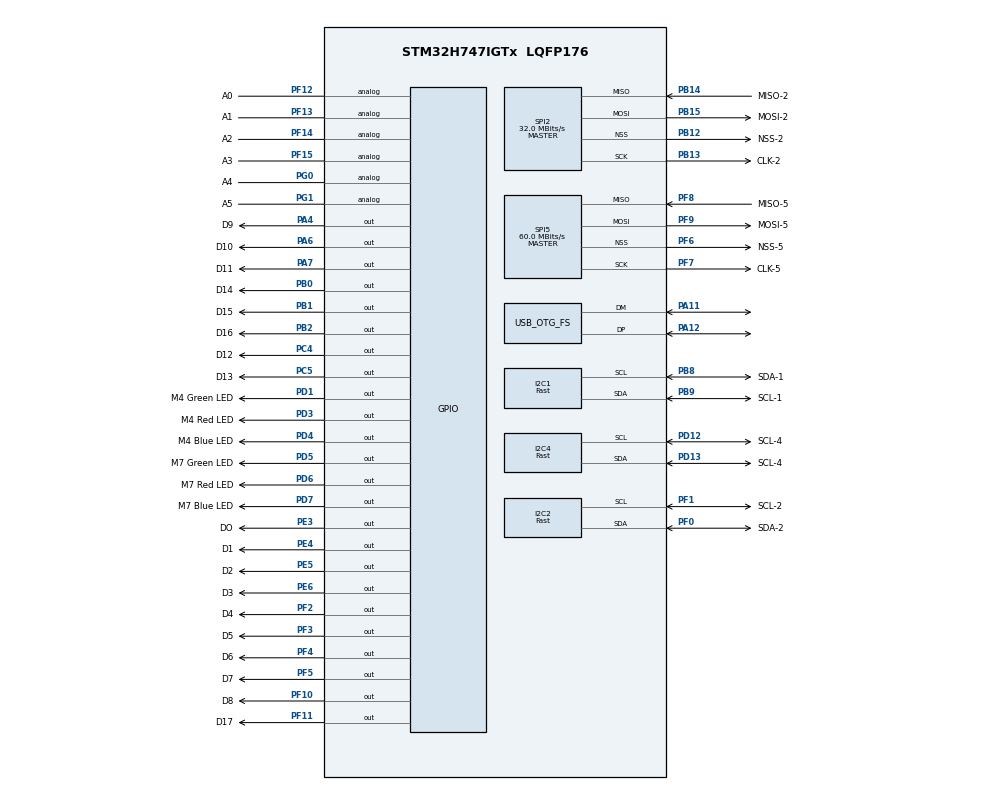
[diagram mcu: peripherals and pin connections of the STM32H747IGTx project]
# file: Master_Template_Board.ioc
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CORTEX_M7.CPU_DCache=Enabled
CORTEX_M7.CPU_ICache=Enabled
CORTEX_M7.default_mode_Activation=1
CortexM4.IPs=CORTEX_M4\:I,FATFS_M4\:I,FREERTOS_M4\:I,IWDG2\:I,OPENAMP_M4\:I,PDM2PCM_M4\:I,PWR,RCC,RESMGR_UTILITY,SYS_M4\:I,USB_DEVICE_M4\:I,USB_HOST_M4\:I,VREFBUF,WWDG2\:I,GPIO,DMA,BDMA,MDMA,NVIC2\:I,I2C1,I2C2,I2C4,SPI2,SPI5,DEBUG
CortexM4.Pins=PE3,PE4,PE5,PE6,PF2,PF3,PF4,PF5,PF10,PA4,PA6,PA7,PC4,PC5,PB0,PB1,PB2,PF11,PF12,PF13,PF14,PF15,PG0,PG1,PD1,PD3,PD4
CortexM7.IPs=CORTEX_M7\:I,FATFS_M7\:I,FREERTOS_M7\:I,IWDG1\:I,OPENAMP_M7\:I,PDM2PCM_M7\:I,PWR\:I,RCC\:I,RESMGR_UTILITY\:I,SYS\:I,USB_DEVICE_M7\:I,USB_HOST_M7\:I,VREFBUF\:I,WWDG1\:I,GPIO\:I,DMA\:I,BDMA\:I,MDMA\:I,NVIC1\:I,I2C1\:I,I2C2\:I,I2C4\:I,SPI2\:I,SPI5\:I,USB_OTG_FS\:I,DEBUG\:I,MEMORYMAP\:I
CortexM7.Pins=PD5,PD6,PD7
I2C1.I2C_Speed_Mode=I2C_Fast
I2C1.Timing=0x00B03FDB
I2C2.I2C_Speed_Mode=I2C_Fast
I2C2.Timing=0x00B03FDB
I2C4.I2C_Speed_Mode=I2C_Fast
I2C4.Timing=0x00B03FDB
Mcu.Family=STM32H7
Mcu.Name=STM32H747IGTx
Mcu.Package=LQFP176
NVIC1.OTG_FS_IRQn=true\:0\:0\:false\:false\:true\:false\:true\:true
NVIC1.PriorityGroup=NVIC_PRIORITYGROUP_4
NVIC2.PriorityGroup=NVIC_PRIORITYGROUP_4
PA11.GPIO_Speed=GPIO_SPEED_FREQ_VERY_HIGH
PA11.Mode=Device_Only
PA11.PinAttribute=CortexM7
PA11.Signal=USB_OTG_FS_DM
PA12.GPIO_Speed=GPIO_SPEED_FREQ_VERY_HIGH
PA12.Mode=Device_Only
PA12.PinAttribute=CortexM7
PA12.Signal=USB_OTG_FS_DP
PA4.GPIO_Label=D9
PA4.GPIO_Speed=GPIO_SPEED_FREQ_VERY_HIGH
PA4.PinAttribute=CortexM4
PA4.Signal=GPIO_Output
PA6.GPIO_Label=D10
PA6.GPIO_Speed=GPIO_SPEED_FREQ_VERY_HIGH
PA6.PinAttribute=CortexM4
PA6.Signal=GPIO_Output
PA7.GPIO_Label=D11
PA7.GPIO_Speed=GPIO_SPEED_FREQ_VERY_HIGH
PA7.PinAttribute=CortexM4
PA7.Signal=GPIO_Output
PB0.GPIO_Label=D14
PB0.GPIO_Speed=GPIO_SPEED_FREQ_VERY_HIGH
PB0.PinAttribute=CortexM4
PB0.Signal=GPIO_Output
PB1.GPIO_Label=D15
PB1.GPIO_Speed=GPIO_SPEED_FREQ_VERY_HIGH
PB1.PinAttribute=CortexM4
PB1.Signal=GPIO_Output
PB12.GPIO_Label=NSS-2
PB12.GPIO_Speed=GPIO_SPEED_FREQ_VERY_HIGH
PB12.Mode=NSS_Signal_Hard_Output
PB12.PinAttribute=CortexM7
PB12.Signal=SPI2_NSS
PB13.GPIO_Label=CLK-2
PB13.Mode=Full_Duplex_Master
PB13.PinAttribute=CortexM7
PB13.Signal=SPI2_SCK
PB14.GPIO_Label=MISO-2
PB14.GPIO_Speed=GPIO_SPEED_FREQ_VERY_HIGH
PB14.Mode=Full_Duplex_Master
PB14.PinAttribute=CortexM7
PB14.Signal=SPI2_MISO
PB15.GPIO_Label=MOSI-2
PB15.GPIO_Speed=GPIO_SPEED_FREQ_VERY_HIGH
PB15.Mode=Full_Duplex_Master
PB15.PinAttribute=CortexM7
PB15.Signal=SPI2_MOSI
PB2.GPIO_Label=D16
PB2.GPIO_Speed=GPIO_SPEED_FREQ_VERY_HIGH
PB2.PinAttribute=CortexM4
PB2.Signal=GPIO_Output
PB8.GPIO_Label=SDA-1
PB8.GPIO_Speed=GPIO_SPEED_FREQ_VERY_HIGH
PB8.Mode=I2C
PB8.PinAttribute=CortexM7
PB8.Signal=I2C1_SCL
PB9.GPIO_Label=SCL-1
PB9.GPIO_Speed=GPIO_SPEED_FREQ_VERY_HIGH
PB9.Mode=I2C
PB9.PinAttribute=CortexM7
PB9.Signal=I2C1_SDA
PC14-OSC32_IN\ (OSC32_IN).Mode=LSE-External-Oscillator
PC14-OSC32_IN\ (OSC32_IN).PinAttribute=Free
PC14-OSC32_IN\ (OSC32_IN).Signal=RCC_OSC32_IN
PC15-OSC32_OUT\ (OSC32_OUT).Mode=LSE-External-Oscillator
PC15-OSC32_OUT\ (OSC32_OUT).PinAttribute=Free
PC15-OSC32_OUT\ (OSC32_OUT).Signal=RCC_OSC32_OUT
PC4.GPIO_Label=D12
PC4.GPIO_Speed=GPIO_SPEED_FREQ_VERY_HIGH
PC4.PinAttribute=CortexM4
PC4.Signal=GPIO_Output
PC5.GPIO_Label=D13
PC5.GPIO_Speed=GPIO_SPEED_FREQ_VERY_HIGH
PC5.PinAttribute=CortexM4
PC5.Signal=GPIO_Output
PD1.GPIO_Label=M4 Green LED
PD1.GPIO_Speed=GPIO_SPEED_FREQ_VERY_HIGH
PD1.PinAttribute=CortexM4
PD1.PinState=GPIO_PIN_SET
PD1.Signal=GPIO_Output
PD12.GPIO_Label=SCL-4
PD12.GPIO_Speed=GPIO_SPEED_FREQ_VERY_HIGH
PD12.Mode=I2C
PD12.PinAttribute=CortexM7
PD12.Signal=I2C4_SCL
PD13.GPIO_Label=SCL-4
PD13.GPIO_Speed=GPIO_SPEED_FREQ_VERY_HIGH
PD13.Mode=I2C
PD13.PinAttribute=CortexM7
PD13.Signal=I2C4_SDA
PD3.GPIO_Label=M4 Red LED
PD3.GPIO_Speed=GPIO_SPEED_FREQ_VERY_HIGH
PD3.PinAttribute=CortexM4
PD3.PinState=GPIO_PIN_SET
PD3.Signal=GPIO_Output
PD4.GPIO_Label=M4 Blue LED
PD4.GPIO_Speed=GPIO_SPEED_FREQ_VERY_HIGH
PD4.PinAttribute=CortexM4
PD4.PinState=GPIO_PIN_SET
PD4.Signal=GPIO_Output
PD5.GPIO_Label=M7 Green LED
PD5.GPIO_Speed=GPIO_SPEED_FREQ_VERY_HIGH
PD5.PinAttribute=CortexM7
PD5.PinState=GPIO_PIN_SET
PD5.Signal=GPIO_Output
PD6.GPIO_Label=M7 Red LED
PD6.GPIO_Speed=GPIO_SPEED_FREQ_VERY_HIGH
PD6.PinAttribute=CortexM7
PD6.PinState=GPIO_PIN_SET
PD6.Signal=GPIO_Output
PD7.GPIO_Label=M7 Blue LED
PD7.GPIO_Speed=GPIO_SPEED_FREQ_VERY_HIGH
PD7.PinAttribute=CortexM7
PD7.PinState=GPIO_PIN_SET
PD7.Signal=GPIO_Output
PE3.GPIO_Label=DO
PE3.GPIO_Speed=GPIO_SPEED_FREQ_VERY_HIGH
PE3.PinAttribute=CortexM4
PE3.Signal=GPIO_Output
PE4.GPIO_Label=D1
PE4.GPIO_Speed=GPIO_SPEED_FREQ_VERY_HIGH
PE4.PinAttribute=CortexM4
PE4.PinState=GPIO_PIN_RESET
PE4.Signal=GPIO_Output
PE5.GPIO_Label=D2
PE5.GPIO_Speed=GPIO_SPEED_FREQ_VERY_HIGH
PE5.PinAttribute=CortexM4
PE5.Signal=GPIO_Output
PE6.GPIO_Label=D3
PE6.GPIO_Speed=GPIO_SPEED_FREQ_VERY_HIGH
PE6.PinAttribute=CortexM4
PE6.Signal=GPIO_Output
PF0.GPIO_Label=SDA-2
PF0.GPIO_Speed=GPIO_SPEED_FREQ_VERY_HIGH
PF0.Mode=I2C
PF0.PinAttribute=CortexM7
PF0.Signal=I2C2_SDA
PF1.GPIO_Label=SCL-2
PF1.GPIO_Speed=GPIO_SPEED_FREQ_VERY_HIGH
PF1.Mode=I2C
PF1.PinAttribute=CortexM7
PF1.Signal=I2C2_SCL
PF10.GPIO_Label=D8
PF10.GPIO_Speed=GPIO_SPEED_FREQ_VERY_HIGH
PF10.PinAttribute=CortexM4
PF10.Signal=GPIO_Output
PF11.GPIO_Label=D17
PF11.GPIO_Speed=GPIO_SPEED_FREQ_VERY_HIGH
PF11.PinAttribute=CortexM4
PF11.Signal=GPIO_Output
PF12.GPIO_Label=A0
PF12.PinAttribute=CortexM4
PF12.Signal=GPIO_Analog
PF13.GPIO_Label=A1
PF13.PinAttribute=CortexM4
PF13.Signal=GPIO_Analog
PF14.GPIO_Label=A2
PF14.PinAttribute=CortexM4
PF14.Signal=GPIO_Analog
PF15.GPIO_Label=A3
PF15.PinAttribute=CortexM4
PF15.Signal=GPIO_Analog
PF2.GPIO_Label=D4
PF2.GPIO_Speed=GPIO_SPEED_FREQ_VERY_HIGH
PF2.PinAttribute=CortexM4
PF2.Signal=GPIO_Output
PF3.GPIO_Label=D5
PF3.GPIO_Speed=GPIO_SPEED_FREQ_VERY_HIGH
PF3.PinAttribute=CortexM4
PF3.Signal=GPIO_Output
PF4.GPIO_Label=D6
PF4.GPIO_Speed=GPIO_SPEED_FREQ_VERY_HIGH
PF4.PinAttribute=CortexM4
PF4.Signal=GPIO_Output
PF5.GPIO_Label=D7
PF5.GPIO_Speed=GPIO_SPEED_FREQ_VERY_HIGH
PF5.PinAttribute=CortexM4
PF5.Signal=GPIO_Output
PF6.GPIO_Label=NSS-5
PF6.GPIO_Speed=GPIO_SPEED_FREQ_VERY_HIGH
PF6.Mode=NSS_Signal_Hard_Output
PF6.PinAttribute=CortexM7
PF6.Signal=SPI5_NSS
PF7.GPIO_Label=CLK-5
PF7.GPIO_Speed=GPIO_SPEED_FREQ_VERY_HIGH
PF7.Mode=Full_Duplex_Master
PF7.PinAttribute=CortexM7
PF7.Signal=SPI5_SCK
PF8.GPIO_Label=MISO-5
PF8.GPIO_Speed=GPIO_SPEED_FREQ_VERY_HIGH
PF8.Mode=Full_Duplex_Master
PF8.PinAttribute=CortexM7
PF8.Signal=SPI5_MISO
PF9.GPIO_Label=MOSI-5
PF9.GPIO_Speed=GPIO_SPEED_FREQ_VERY_HIGH
PF9.Mode=Full_Duplex_Master
PF9.PinAttribute=CortexM7
PF9.Signal=SPI5_MOSI
PG0.GPIO_Label=A4
PG0.PinAttribute=CortexM4
PG0.Signal=GPIO_Analog
PG1.GPIO_Label=A5
PG1.PinAttribute=CortexM4
PG1.Signal=GPIO_Analog
PH0-OSC_IN\ (PH0).Mode=HSE-External-Oscillator
PH0-OSC_IN\ (PH0).PinAttribute=Free
PH0-OSC_IN\ (PH0).Signal=RCC_OSC_IN
PH1-OSC_OUT\ (PH1).Mode=HSE-External-Oscillator
PH1-OSC_OUT\ (PH1).PinAttribute=Free
PH1-OSC_OUT\ (PH1).Signal=RCC_OSC_OUT
ProjectManager.HeapSize=M4-0x200,M7-0x200
ProjectManager.StackSize=M4-0x400,M7-0x400
ProjectManager.TargetToolchain=STM32CubeIDE
RCC.ADCFreq_Value=80000000
RCC.APB1Freq_Value=120000000
RCC.APB2Freq_Value=120000000
RCC.APB3Freq_Value=120000000
RCC.APB4Freq_Value=120000000
RCC.CortexFreq_Value=480000000
RCC.D1PPRE=RCC_APB3_DIV2
RCC.D2PPRE1=RCC_APB1_DIV2
RCC.D2PPRE2=RCC_APB2_DIV2
RCC.D3PPRE=RCC_APB4_DIV2
RCC.DIVM1=2
RCC.DIVM2=1
RCC.DIVN1=120
RCC.DIVN2=10
RCC.HCLKFreq_Value=240000000
RCC.HPRE=RCC_HCLK_DIV2
RCC.HSE_VALUE=16000000
RCC.PLLSourceVirtual=RCC_PLLSOURCE_HSE
RCC.SPI123CLockSelection=RCC_SPI123CLKSOURCE_CLKP
RCC.SYSCLKFreq_VALUE=480000000
RCC.SYSCLKSource=RCC_SYSCLKSOURCE_PLLCLK
RCC.USBCLockSelection=RCC_USBCLKSOURCE_HSI48
RCC.USBFreq_Value=48000000
SPI2.BaudRatePrescaler=SPI_BAUDRATEPRESCALER_2
SPI2.CalculateBaudRate=32.0 MBits/s
SPI2.DataSize=SPI_DATASIZE_16BIT
SPI2.Direction=SPI_DIRECTION_2LINES
SPI2.Mode=SPI_MODE_MASTER
SPI2.VirtualNSS=VM_NSSHARD
SPI2.VirtualType=VM_MASTER
SPI5.BaudRatePrescaler=SPI_BAUDRATEPRESCALER_2
SPI5.CalculateBaudRate=60.0 MBits/s
SPI5.DataSize=SPI_DATASIZE_16BIT
SPI5.Direction=SPI_DIRECTION_2LINES
SPI5.Mode=SPI_MODE_MASTER
SPI5.VirtualNSS=VM_NSSHARD
SPI5.VirtualType=VM_MASTER
SYS.userName=SYS_M7
USB_DEVICE_M7.CLASS_NAME_FS=CDC
USB_DEVICE_M7.VirtualMode-CDC_FS=Cdc
USB_DEVICE_M7.VirtualModeFS=Cdc_FS
USB_OTG_FS.VirtualMode=Device_Only
VP_MEMORYMAP_VS_MEMORYMAP.Mode=CurAppReg
VP_SYS_M4_VS_Systick.Mode=SysTick
VP_USB_DEVICE_M7_VS_USB_DEVICE_CDC_FS.Mode=CDC_FS
board=custom

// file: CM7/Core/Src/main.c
/* USER CODE BEGIN Header */
/**
  ******************************************************************************
  * @file           : main.c
  * @brief          : Main program body
  ******************************************************************************
  * @attention
  *
  * Copyright (c) 2025 STMicroelectronics.
  * All rights reserved.
  *
  * This software is licensed under terms that can be found in the LICENSE file
  * in the root directory of this software component.
  * If no LICENSE file comes with this software, it is provided AS-IS.
  *
  ******************************************************************************
  */
/* USER CODE END Header */
#include "main.h"
#include "usb_device.h"

/* USER CODE BEGIN Includes */
#include "M7_Configuration.h"
/* USER CODE END Includes */

/* USER CODE BEGIN PD */

#ifndef HSEM_ID_0
#define HSEM_ID_0 (0U) /* HW semaphore 0*/
#endif

/* USER CODE END PD */

I2C_HandleTypeDef hi2c1;
I2C_HandleTypeDef hi2c2;
I2C_HandleTypeDef hi2c4;

SPI_HandleTypeDef hspi2;
SPI_HandleTypeDef hspi5;

void SystemClock_Config(void);
void PeriphCommonClock_Config(void);
static void MPU_Config(void);
static void MX_GPIO_Init(void);
static void MX_I2C1_Init(void);
static void MX_I2C2_Init(void);
static void MX_I2C4_Init(void);
static void MX_SPI2_Init(void);
static void MX_SPI5_Init(void);

int main(void)
{

/* USER CODE BEGIN Boot_Mode_Sequence_0 */
  int32_t timeout;
/* USER CODE END Boot_Mode_Sequence_0 */

  /* MPU Configuration--------------------------------------------------------*/
  MPU_Config();

  /* Enable the CPU Cache */

  /* Enable I-Cache---------------------------------------------------------*/
  SCB_EnableICache();

  /* Enable D-Cache---------------------------------------------------------*/
  SCB_EnableDCache();

/* USER CODE BEGIN Boot_Mode_Sequence_1 */
  /* Wait until CPU2 boots and enters in stop mode or timeout*/
  timeout = 0xFFFF;
  while((__HAL_RCC_GET_FLAG(RCC_FLAG_D2CKRDY) != RESET) && (timeout-- > 0));
  if ( timeout < 0 )
  {
  Error_Handler();
  }
/* USER CODE END Boot_Mode_Sequence_1 */
  /* MCU Configuration--------------------------------------------------------*/

  /* Reset of all peripherals, Initializes the Flash interface and the Systick. */
  HAL_Init();

  /* Configure the system clock */
  SystemClock_Config();

  /* Configure the peripherals common clocks */
  PeriphCommonClock_Config();
/* USER CODE BEGIN Boot_Mode_Sequence_2 */
/* When system initialization is finished, Cortex-M7 will release Cortex-M4 by means of
HSEM notification */
/*HW semaphore Clock enable*/
__HAL_RCC_HSEM_CLK_ENABLE();
/*Take HSEM */
HAL_HSEM_FastTake(HSEM_ID_0);
/*Release HSEM in order to notify the CPU2(CM4)*/
HAL_HSEM_Release(HSEM_ID_0,0);
/* wait until CPU2 wakes up from stop mode */
timeout = 0xFFFF;
while((__HAL_RCC_GET_FLAG(RCC_FLAG_D2CKRDY) == RESET) && (timeout-- > 0));
if ( timeout < 0 )
{
Error_Handler();
}
/* USER CODE END Boot_Mode_Sequence_2 */

  /* Initialize all configured peripherals */
  MX_GPIO_Init();
  MX_I2C1_Init();
  MX_I2C2_Init();
  MX_I2C4_Init();
  MX_SPI2_Init();
  MX_SPI5_Init();
  MX_USB_DEVICE_Init();
  /* USER CODE BEGIN 2 */
  ConfigurationInit();
  MPU_Config_D2_NonCacheable();
  setup();
  LED_on(&myLED, "blue") ;
  delay(1000);
  /* USER CODE END 2 */

  /* Infinite loop */
  while (1)
  {

    /* USER CODE BEGIN 3 */
	Data_Input();
	loop();
  }
  /* USER CODE END 3 */
}

void SystemClock_Config(void)
{
  RCC_OscInitTypeDef RCC_OscInitStruct = {0};
  RCC_ClkInitTypeDef RCC_ClkInitStruct = {0};

  /** Supply configuration update enable
  */
  HAL_PWREx_ConfigSupply(PWR_LDO_SUPPLY);

  /** Configure the main internal regulator output voltage
  */
  __HAL_PWR_VOLTAGESCALING_CONFIG(PWR_REGULATOR_VOLTAGE_SCALE0);

  while(!__HAL_PWR_GET_FLAG(PWR_FLAG_VOSRDY)) {}

  /** Initializes the RCC Oscillators according to the specified parameters
  * in the RCC_OscInitTypeDef structure.
  */
  RCC_OscInitStruct.OscillatorType = RCC_OSCILLATORTYPE_HSI48|RCC_OSCILLATORTYPE_HSI
                              |RCC_OSCILLATORTYPE_HSE;
  RCC_OscInitStruct.HSEState = RCC_HSE_ON;
  RCC_OscInitStruct.HSIState = RCC_HSI_DIV1;
  RCC_OscInitStruct.HSICalibrationValue = RCC_HSICALIBRATION_DEFAULT;
  RCC_OscInitStruct.HSI48State = RCC_HSI48_ON;
  RCC_OscInitStruct.PLL.PLLState = RCC_PLL_ON;
  RCC_OscInitStruct.PLL.PLLSource = RCC_PLLSOURCE_HSE;
  RCC_OscInitStruct.PLL.PLLM = 2;
  RCC_OscInitStruct.PLL.PLLN = 120;
  RCC_OscInitStruct.PLL.PLLP = 2;
  RCC_OscInitStruct.PLL.PLLQ = 2;
  RCC_OscInitStruct.PLL.PLLR = 2;
  RCC_OscInitStruct.PLL.PLLRGE = RCC_PLL1VCIRANGE_3;
  RCC_OscInitStruct.PLL.PLLVCOSEL = RCC_PLL1VCOWIDE;
  RCC_OscInitStruct.PLL.PLLFRACN = 0;
  if (HAL_RCC_OscConfig(&RCC_OscInitStruct) != HAL_OK)
  {
    Error_Handler();
  }

  /** Initializes the CPU, AHB and APB buses clocks
  */
  RCC_ClkInitStruct.ClockType = RCC_CLOCKTYPE_HCLK|RCC_CLOCKTYPE_SYSCLK
                              |RCC_CLOCKTYPE_PCLK1|RCC_CLOCKTYPE_PCLK2
                              |RCC_CLOCKTYPE_D3PCLK1|RCC_CLOCKTYPE_D1PCLK1;
  RCC_ClkInitStruct.SYSCLKSource = RCC_SYSCLKSOURCE_PLLCLK;
  RCC_ClkInitStruct.SYSCLKDivider = RCC_SYSCLK_DIV1;
  RCC_ClkInitStruct.AHBCLKDivider = RCC_HCLK_DIV2;
  RCC_ClkInitStruct.APB3CLKDivider = RCC_APB3_DIV2;
  RCC_ClkInitStruct.APB1CLKDivider = RCC_APB1_DIV2;
  RCC_ClkInitStruct.APB2CLKDivider = RCC_APB2_DIV2;
  RCC_ClkInitStruct.APB4CLKDivider = RCC_APB4_DIV2;

  if (HAL_RCC_ClockConfig(&RCC_ClkInitStruct, FLASH_LATENCY_4) != HAL_OK)
  {
    Error_Handler();
  }
}

void PeriphCommonClock_Config(void)
{
  RCC_PeriphCLKInitTypeDef PeriphClkInitStruct = {0};

  /** Initializes the peripherals clock
  */
  PeriphClkInitStruct.PeriphClockSelection = RCC_PERIPHCLK_CKPER;
  PeriphClkInitStruct.CkperClockSelection = RCC_CLKPSOURCE_HSI;
  if (HAL_RCCEx_PeriphCLKConfig(&PeriphClkInitStruct) != HAL_OK)
  {
    Error_Handler();
  }
}

static void MX_I2C1_Init(void)
{

  hi2c1.Instance = I2C1;
  hi2c1.Init.Timing = 0x00B03FDB;
  hi2c1.Init.OwnAddress1 = 0;
  hi2c1.Init.AddressingMode = I2C_ADDRESSINGMODE_7BIT;
  hi2c1.Init.DualAddressMode = I2C_DUALADDRESS_DISABLE;
  hi2c1.Init.OwnAddress2 = 0;
  hi2c1.Init.OwnAddress2Masks = I2C_OA2_NOMASK;
  hi2c1.Init.GeneralCallMode = I2C_GENERALCALL_DISABLE;
  hi2c1.Init.NoStretchMode = I2C_NOSTRETCH_DISABLE;
  if (HAL_I2C_Init(&hi2c1) != HAL_OK)
  {
    Error_Handler();
  }

  /** Configure Analogue filter
  */
  if (HAL_I2CEx_ConfigAnalogFilter(&hi2c1, I2C_ANALOGFILTER_ENABLE) != HAL_OK)
  {
    Error_Handler();
  }

  /** Configure Digital filter
  */
  if (HAL_I2CEx_ConfigDigitalFilter(&hi2c1, 0) != HAL_OK)
  {
    Error_Handler();
  }

}

static void MX_I2C2_Init(void)
{

  hi2c2.Instance = I2C2;
  hi2c2.Init.Timing = 0x00B03FDB;
  hi2c2.Init.OwnAddress1 = 0;
  hi2c2.Init.AddressingMode = I2C_ADDRESSINGMODE_7BIT;
  hi2c2.Init.DualAddressMode = I2C_DUALADDRESS_DISABLE;
  hi2c2.Init.OwnAddress2 = 0;
  hi2c2.Init.OwnAddress2Masks = I2C_OA2_NOMASK;
  hi2c2.Init.GeneralCallMode = I2C_GENERALCALL_DISABLE;
  hi2c2.Init.NoStretchMode = I2C_NOSTRETCH_DISABLE;
  if (HAL_I2C_Init(&hi2c2) != HAL_OK)
  {
    Error_Handler();
  }

  /** Configure Analogue filter
  */
  if (HAL_I2CEx_ConfigAnalogFilter(&hi2c2, I2C_ANALOGFILTER_ENABLE) != HAL_OK)
  {
    Error_Handler();
  }

  /** Configure Digital filter
  */
  if (HAL_I2CEx_ConfigDigitalFilter(&hi2c2, 0) != HAL_OK)
  {
    Error_Handler();
  }

}

static void MX_I2C4_Init(void)
{

  hi2c4.Instance = I2C4;
  hi2c4.Init.Timing = 0x00B03FDB;
  hi2c4.Init.OwnAddress1 = 0;
  hi2c4.Init.AddressingMode = I2C_ADDRESSINGMODE_7BIT;
  hi2c4.Init.DualAddressMode = I2C_DUALADDRESS_DISABLE;
  hi2c4.Init.OwnAddress2 = 0;
  hi2c4.Init.OwnAddress2Masks = I2C_OA2_NOMASK;
  hi2c4.Init.GeneralCallMode = I2C_GENERALCALL_DISABLE;
  hi2c4.Init.NoStretchMode = I2C_NOSTRETCH_DISABLE;
  if (HAL_I2C_Init(&hi2c4) != HAL_OK)
  {
    Error_Handler();
  }

  /** Configure Analogue filter
  */
  if (HAL_I2CEx_ConfigAnalogFilter(&hi2c4, I2C_ANALOGFILTER_ENABLE) != HAL_OK)
  {
    Error_Handler();
  }

  /** Configure Digital filter
  */
  if (HAL_I2CEx_ConfigDigitalFilter(&hi2c4, 0) != HAL_OK)
  {
    Error_Handler();
  }

}

static void MX_SPI2_Init(void)
{

  /* SPI2 parameter configuration*/
  hspi2.Instance = SPI2;
  hspi2.Init.Mode = SPI_MODE_MASTER;
  hspi2.Init.Direction = SPI_DIRECTION_2LINES;
  hspi2.Init.DataSize = SPI_DATASIZE_16BIT;
  hspi2.Init.CLKPolarity = SPI_POLARITY_LOW;
  hspi2.Init.CLKPhase = SPI_PHASE_1EDGE;
  hspi2.Init.NSS = SPI_NSS_HARD_OUTPUT;
  hspi2.Init.BaudRatePrescaler = SPI_BAUDRATEPRESCALER_2;
  hspi2.Init.FirstBit = SPI_FIRSTBIT_MSB;
  hspi2.Init.TIMode = SPI_TIMODE_DISABLE;
  hspi2.Init.CRCCalculation = SPI_CRCCALCULATION_DISABLE;
  hspi2.Init.CRCPolynomial = 0x0;
  hspi2.Init.NSSPMode = SPI_NSS_PULSE_ENABLE;
  hspi2.Init.NSSPolarity = SPI_NSS_POLARITY_LOW;
  hspi2.Init.FifoThreshold = SPI_FIFO_THRESHOLD_01DATA;
  hspi2.Init.TxCRCInitializationPattern = SPI_CRC_INITIALIZATION_ALL_ZERO_PATTERN;
  hspi2.Init.RxCRCInitializationPattern = SPI_CRC_INITIALIZATION_ALL_ZERO_PATTERN;
  hspi2.Init.MasterSSIdleness = SPI_MASTER_SS_IDLENESS_00CYCLE;
  hspi2.Init.MasterInterDataIdleness = SPI_MASTER_INTERDATA_IDLENESS_00CYCLE;
  hspi2.Init.MasterReceiverAutoSusp = SPI_MASTER_RX_AUTOSUSP_DISABLE;
  hspi2.Init.MasterKeepIOState = SPI_MASTER_KEEP_IO_STATE_DISABLE;
  hspi2.Init.IOSwap = SPI_IO_SWAP_DISABLE;
  if (HAL_SPI_Init(&hspi2) != HAL_OK)
  {
    Error_Handler();
  }

}

static void MX_SPI5_Init(void)
{

  /* SPI5 parameter configuration*/
  hspi5.Instance = SPI5;
  hspi5.Init.Mode = SPI_MODE_MASTER;
  hspi5.Init.Direction = SPI_DIRECTION_2LINES;
  hspi5.Init.DataSize = SPI_DATASIZE_16BIT;
  hspi5.Init.CLKPolarity = SPI_POLARITY_LOW;
  hspi5.Init.CLKPhase = SPI_PHASE_1EDGE;
  hspi5.Init.NSS = SPI_NSS_HARD_OUTPUT;
  hspi5.Init.BaudRatePrescaler = SPI_BAUDRATEPRESCALER_2;
  hspi5.Init.FirstBit = SPI_FIRSTBIT_MSB;
  hspi5.Init.TIMode = SPI_TIMODE_DISABLE;
  hspi5.Init.CRCCalculation = SPI_CRCCALCULATION_DISABLE;
  hspi5.Init.CRCPolynomial = 0x0;
  hspi5.Init.NSSPMode = SPI_NSS_PULSE_ENABLE;
  hspi5.Init.NSSPolarity = SPI_NSS_POLARITY_LOW;
  hspi5.Init.FifoThreshold = SPI_FIFO_THRESHOLD_01DATA;
  hspi5.Init.TxCRCInitializationPattern = SPI_CRC_INITIALIZATION_ALL_ZERO_PATTERN;
  hspi5.Init.RxCRCInitializationPattern = SPI_CRC_INITIALIZATION_ALL_ZERO_PATTERN;
  hspi5.Init.MasterSSIdleness = SPI_MASTER_SS_IDLENESS_00CYCLE;
  hspi5.Init.MasterInterDataIdleness = SPI_MASTER_INTERDATA_IDLENESS_00CYCLE;
  hspi5.Init.MasterReceiverAutoSusp = SPI_MASTER_RX_AUTOSUSP_DISABLE;
  hspi5.Init.MasterKeepIOState = SPI_MASTER_KEEP_IO_STATE_DISABLE;
  hspi5.Init.IOSwap = SPI_IO_SWAP_DISABLE;
  if (HAL_SPI_Init(&hspi5) != HAL_OK)
  {
    Error_Handler();
  }

}

static void MX_GPIO_Init(void)
{
  GPIO_InitTypeDef GPIO_InitStruct = {0};

  /* GPIO Ports Clock Enable */
  __HAL_RCC_GPIOF_CLK_ENABLE();
  __HAL_RCC_GPIOB_CLK_ENABLE();
  __HAL_RCC_GPIOD_CLK_ENABLE();
  __HAL_RCC_GPIOA_CLK_ENABLE();

  /*Configure GPIO pin Output Level */
  HAL_GPIO_WritePin(GPIOD, M7_Green_LED_Pin|M7_Red_LED_Pin|M7_Blue_LED_Pin, GPIO_PIN_SET);

  /*Configure GPIO pins : M7_Green_LED_Pin M7_Red_LED_Pin M7_Blue_LED_Pin */
  GPIO_InitStruct.Pin = M7_Green_LED_Pin|M7_Red_LED_Pin|M7_Blue_LED_Pin;
  GPIO_InitStruct.Mode = GPIO_MODE_OUTPUT_PP;
  GPIO_InitStruct.Pull = GPIO_NOPULL;
  GPIO_InitStruct.Speed = GPIO_SPEED_FREQ_VERY_HIGH;
  HAL_GPIO_Init(GPIOD, &GPIO_InitStruct);

}

 /* MPU Configuration */

void MPU_Config(void)
{
  MPU_Region_InitTypeDef MPU_InitStruct = {0};

  /* Disables the MPU */
  HAL_MPU_Disable();

  /** Initializes and configures the Region and the memory to be protected
  */
  MPU_InitStruct.Enable = MPU_REGION_ENABLE;
  MPU_InitStruct.Number = MPU_REGION_NUMBER0;
  MPU_InitStruct.BaseAddress = 0x0;
  MPU_InitStruct.Size = MPU_REGION_SIZE_4GB;
  MPU_InitStruct.SubRegionDisable = 0x87;
  MPU_InitStruct.TypeExtField = MPU_TEX_LEVEL0;
  MPU_InitStruct.AccessPermission = MPU_REGION_NO_ACCESS;
  MPU_InitStruct.DisableExec = MPU_INSTRUCTION_ACCESS_DISABLE;
  MPU_InitStruct.IsShareable = MPU_ACCESS_SHAREABLE;
  MPU_InitStruct.IsCacheable = MPU_ACCESS_NOT_CACHEABLE;
  MPU_InitStruct.IsBufferable = MPU_ACCESS_NOT_BUFFERABLE;

  HAL_MPU_ConfigRegion(&MPU_InitStruct);
  /* Enables the MPU */
  HAL_MPU_Enable(MPU_PRIVILEGED_DEFAULT);

}

void Error_Handler(void)
{
  __disable_irq();
  while (1)
  {
  }
}
